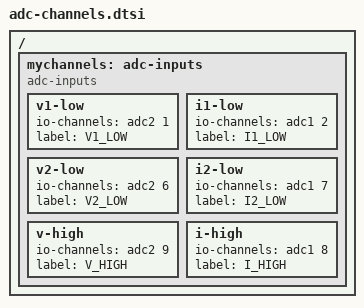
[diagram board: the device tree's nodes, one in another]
/ {
	mychannels: adc-inputs {
		compatible = "adc-inputs";
		v1-low {
			io-channels = <&adc2 1>;
			label = "V1_LOW";
		};

		i1-low {
			io-channels = <&adc1 2>;
			label = "I1_LOW";
		};

		v2-low {
			io-channels = <&adc2 6>;
			label = "V2_LOW";
		};

		i2-low {
			io-channels = <&adc1 7>;
			label = "I2_LOW";
		};

		v-high {
			io-channels = <&adc2 9>;
			label = "V_HIGH";
		};

		i-high {
			io-channels = <&adc1 8>;
			label = "I_HIGH";
		};
	};
};
